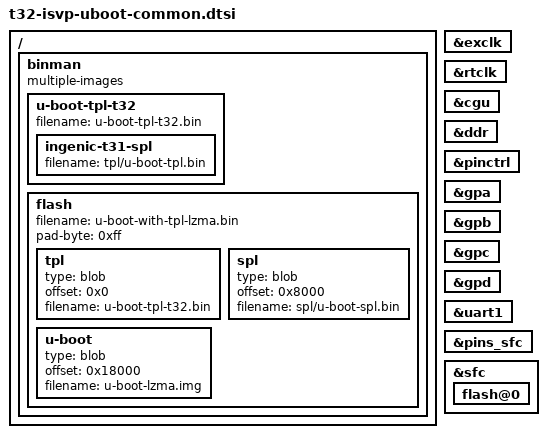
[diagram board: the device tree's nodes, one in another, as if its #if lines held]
// SPDX-License-Identifier: GPL-2.0+
/*
 * Shared U-Boot overlay for the Ingenic ISVP-T32 SFC-NOR leaf DTs.
 * Each per-SKU <leaf>-u-boot.dtsi is a one-line #include of this file
 * (the U-Boot build auto-appends <leaf>-u-boot.dtsi to <leaf>.dts).
 *
 * T32 boots a TPL chain (NOR cold boot + USB). Its NOR mask ROM is uncapped, but
 * a DM + SFC SPL is still split off behind a tiny TPL like every XBurst1 SoC: the
 * ROM loads the headered TPL (NOR offset 0); the TPL brings up DDR in cache-as-RAM
 * and reads the DRAM-resident SPL (NOR 0x8000); the SPL reads U-Boot (NOR 0x18000
 * = CONFIG_SYS_SPI_U_BOOT_OFFS). The 2 KiB header CRC7+length is finalized by the
 * family-generic ingenic-t31-spl binman etype - the T31 mask-ROM contract, shared
 * verbatim by the T32 bootrom.
 *
 * Phase tags: the TPL/SPL devicetrees are fdtgrep-filtered out of the single
 * dt.dtb by bootph tags (TPL keeps bootph-all + bootph-pre-sram; SPL keeps
 * bootph-all + bootph-pre-ram), NOT re-preprocessed per phase. The TPL's only
 * DM device is &ddr (its probe brings up PLL + DDR, then it hand-loads the SPL
 * with bare-metal SFC2/serial helpers), so only &ddr is tagged for all phases;
 * every other node is bootph-pre-ram + bootph-some-ram (present in the SPL DM
 * boot and U-Boot pre-reloc, absent from the minimal TPL).
 */

/ {
	binman: binman {
		multiple-images;
	};
};

&binman {
#if defined(CONFIG_TPL)
	u-boot-tpl-t32 {
		filename = "u-boot-tpl-t32.bin";

		ingenic-t31-spl {
			filename = "tpl/u-boot-tpl.bin";
		};
	};

	flash {
		filename = "u-boot-with-tpl-lzma.bin";
		pad-byte = <0xff>;

		tpl {
			type = "blob";
			offset = <0x0>;
			filename = "u-boot-tpl-t32.bin";
		};

		spl {
			type = "blob";
			offset = <0x8000>;
			filename = "spl/u-boot-spl.bin";
		};

		u-boot {
			type = "blob";
			offset = <0x18000>;
			filename = "u-boot-lzma.img";
		};
	};
#else
	u-boot-spl-t32 {
		filename = "u-boot-spl-t32.bin";

		ingenic-t31-spl {
			filename = "spl/u-boot-spl.bin";
		};
	};

	flash {
		filename = "u-boot-with-spl-lzma.bin";
		pad-byte = <0xff>;

		spl {
			type = "blob";
			offset = <0x0>;
			filename = "u-boot-spl-t32.bin";
		};

		u-boot {
			type = "blob";
			offset = <0x14000>;
			filename = "u-boot-lzma.img";
		};
	};
#endif
};

&exclk { bootph-pre-ram; bootph-some-ram; };
&rtclk { bootph-pre-ram; bootph-some-ram; };
&cgu { bootph-pre-ram; bootph-some-ram; };
&ddr { bootph-all; };		/* the TPL's only DM device; leaf supplies params */
&pinctrl { bootph-pre-ram; bootph-some-ram; };
&gpa { bootph-pre-ram; bootph-some-ram; };
&gpb { bootph-pre-ram; bootph-some-ram; };
&gpc { bootph-pre-ram; bootph-some-ram; };
&gpd { bootph-pre-ram; bootph-some-ram; };
&uart1 { bootph-pre-ram; bootph-some-ram; };

&pins_sfc { bootph-pre-ram; bootph-some-ram; };
&sfc {
	bootph-pre-ram;
	bootph-some-ram;
	flash@0 {
		bootph-pre-ram;
		bootph-some-ram;
	};
};
